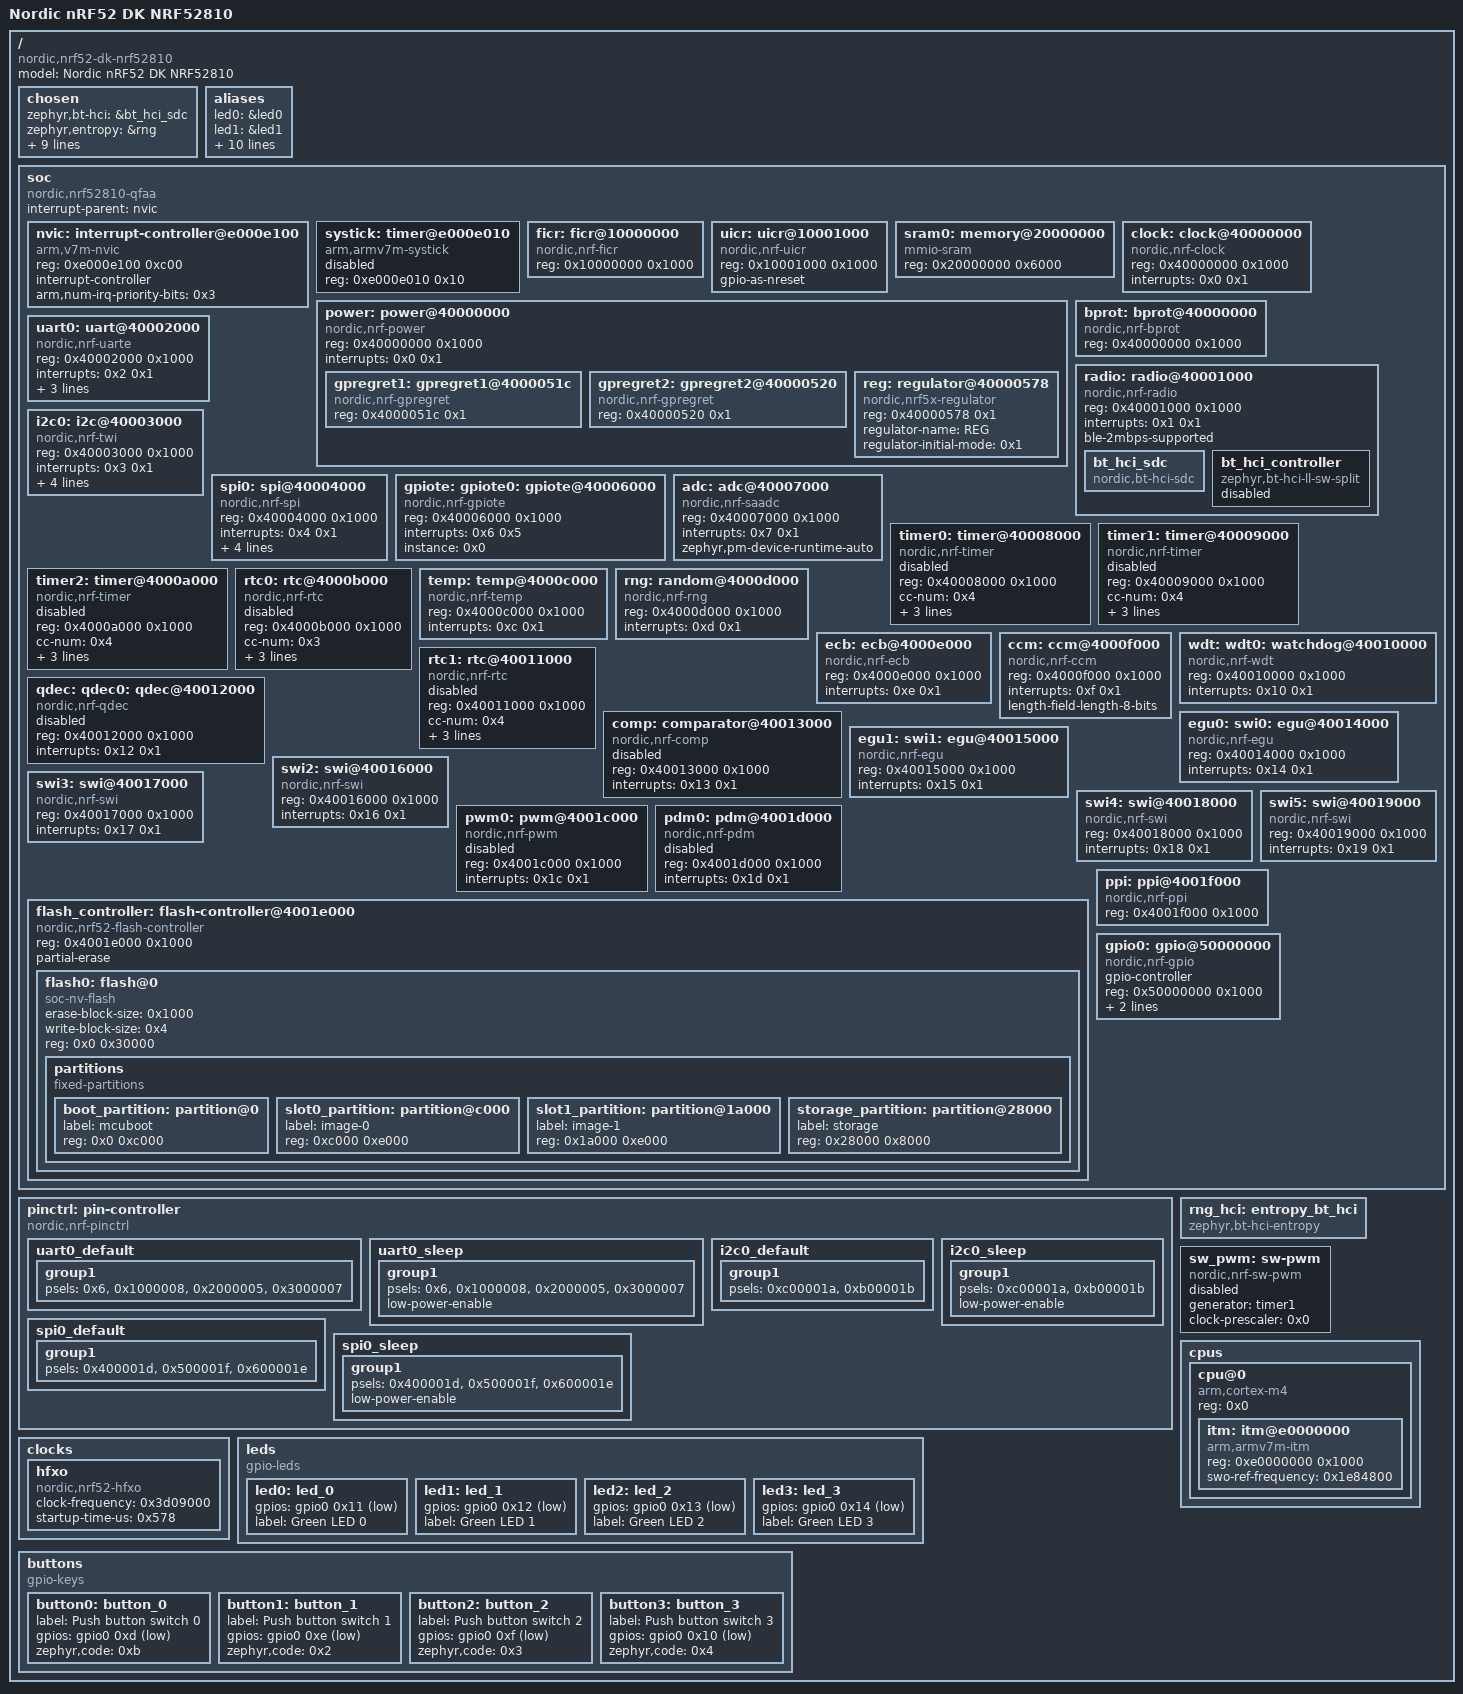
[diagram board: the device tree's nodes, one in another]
/dts-v1/;

/* node '/' defined in zephyr\dts\common\skeleton.dtsi:9 */
/ {
	#address-cells = < 0x1 >;                /* in zephyr\dts\common\skeleton.dtsi:10 */
	#size-cells = < 0x1 >;                   /* in zephyr\dts\common\skeleton.dtsi:11 */
	model = "Nordic nRF52 DK NRF52810";      /* in zephyr\boards\nordic\nrf52dk\nrf52dk_nrf52810.dts:15 */
	compatible = "nordic,nrf52-dk-nrf52810"; /* in zephyr\boards\nordic\nrf52dk\nrf52dk_nrf52810.dts:16 */

	/* node '/chosen' defined in zephyr\dts\common\skeleton.dtsi:12 */
	chosen {
		zephyr,bt-hci = &bt_hci_sdc;                 /* in zephyr\dts\arm\nordic\nrf52810.dtsi:10 */
		zephyr,entropy = &rng;                       /* in zephyr\dts\arm\nordic\nrf52810.dtsi:11 */
		zephyr,flash-controller = &flash_controller; /* in zephyr\dts\arm\nordic\nrf52810.dtsi:12 */
		zephyr,console = &uart0;                     /* in zephyr\boards\nordic\nrf52dk\nrf52dk_nrf52810.dts:19 */
		zephyr,shell-uart = &uart0;                  /* in zephyr\boards\nordic\nrf52dk\nrf52dk_nrf52810.dts:20 */
		zephyr,uart-mcumgr = &uart0;                 /* in zephyr\boards\nordic\nrf52dk\nrf52dk_nrf52810.dts:21 */
		zephyr,bt-mon-uart = &uart0;                 /* in zephyr\boards\nordic\nrf52dk\nrf52dk_nrf52810.dts:22 */
		zephyr,bt-c2h-uart = &uart0;                 /* in zephyr\boards\nordic\nrf52dk\nrf52dk_nrf52810.dts:23 */
		zephyr,sram = &sram0;                        /* in zephyr\boards\nordic\nrf52dk\nrf52dk_nrf52810.dts:24 */
		zephyr,flash = &flash0;                      /* in zephyr\boards\nordic\nrf52dk\nrf52dk_nrf52810.dts:25 */
		zephyr,code-partition = &slot0_partition;    /* in zephyr\boards\nordic\nrf52dk\nrf52dk_nrf52810.dts:26 */
	};

	/* node '/aliases' defined in zephyr\dts\common\skeleton.dtsi:13 */
	aliases {
		led0 = &led0;               /* in zephyr\boards\nordic\nrf52dk\nrf52dk_nrf52810.dts:83 */
		led1 = &led1;               /* in zephyr\boards\nordic\nrf52dk\nrf52dk_nrf52810.dts:84 */
		led2 = &led2;               /* in zephyr\boards\nordic\nrf52dk\nrf52dk_nrf52810.dts:85 */
		led3 = &led3;               /* in zephyr\boards\nordic\nrf52dk\nrf52dk_nrf52810.dts:86 */
		sw0 = &button0;             /* in zephyr\boards\nordic\nrf52dk\nrf52dk_nrf52810.dts:87 */
		sw1 = &button1;             /* in zephyr\boards\nordic\nrf52dk\nrf52dk_nrf52810.dts:88 */
		sw2 = &button2;             /* in zephyr\boards\nordic\nrf52dk\nrf52dk_nrf52810.dts:89 */
		sw3 = &button3;             /* in zephyr\boards\nordic\nrf52dk\nrf52dk_nrf52810.dts:90 */
		bootloader-led0 = &led0;    /* in zephyr\boards\nordic\nrf52dk\nrf52dk_nrf52810.dts:91 */
		mcuboot-button0 = &button0; /* in zephyr\boards\nordic\nrf52dk\nrf52dk_nrf52810.dts:92 */
		mcuboot-led0 = &led0;       /* in zephyr\boards\nordic\nrf52dk\nrf52dk_nrf52810.dts:93 */
		watchdog0 = &wdt0;          /* in zephyr\boards\nordic\nrf52dk\nrf52dk_nrf52810.dts:94 */
	};

	/* node '/soc' defined in zephyr\dts\arm\armv7-m.dtsi:6 */
	soc {
		#address-cells = < 0x1 >;            /* in zephyr\dts\arm\armv7-m.dtsi:7 */
		#size-cells = < 0x1 >;               /* in zephyr\dts\arm\armv7-m.dtsi:8 */
		compatible = "nordic,nrf52810-qfaa",
		             "nordic,nrf52810",
		             "nordic,nrf52",
		             "simple-bus";           /* in zephyr\dts\arm\nordic\nrf52810_qfaa.dtsi:20 */
		interrupt-parent = < &nvic >;        /* in zephyr\dts\arm\armv7-m.dtsi:10 */
		ranges;                              /* in zephyr\dts\arm\armv7-m.dtsi:11 */

		/* node '/soc/interrupt-controller@e000e100' defined in zephyr\dts\arm\armv7-m.dtsi:13 */
		nvic: interrupt-controller@e000e100 {
			#address-cells = < 0x1 >;            /* in zephyr\dts\arm\armv7-m.dtsi:14 */
			compatible = "arm,v7m-nvic";         /* in zephyr\dts\arm\armv7-m.dtsi:15 */
			reg = < 0xe000e100 0xc00 >;          /* in zephyr\dts\arm\armv7-m.dtsi:16 */
			interrupt-controller;                /* in zephyr\dts\arm\armv7-m.dtsi:17 */
			#interrupt-cells = < 0x2 >;          /* in zephyr\dts\arm\armv7-m.dtsi:18 */
			arm,num-irq-priority-bits = < 0x3 >; /* in zephyr\dts\arm\nordic\nrf52810.dtsi:376 */
			phandle = < 0x1 >;                   /* in zephyr\dts\arm\armv7-m.dtsi:10 */
		};

		/* node '/soc/timer@e000e010' defined in zephyr\dts\arm\armv7-m.dtsi:21 */
		systick: timer@e000e010 {
			compatible = "arm,armv7m-systick"; /* in zephyr\dts\arm\armv7-m.dtsi:22 */
			reg = < 0xe000e010 0x10 >;         /* in zephyr\dts\arm\armv7-m.dtsi:23 */
			status = "disabled";               /* in zephyr\dts\arm\nordic\nrf52810.dtsi:381 */
		};

		/* node '/soc/ficr@10000000' defined in zephyr\dts\arm\nordic\nrf52810.dtsi:44 */
		ficr: ficr@10000000 {
			compatible = "nordic,nrf-ficr"; /* in zephyr\dts\arm\nordic\nrf52810.dtsi:45 */
			reg = < 0x10000000 0x1000 >;    /* in zephyr\dts\arm\nordic\nrf52810.dtsi:46 */
			#nordic,ficr-cells = < 0x1 >;   /* in zephyr\dts\arm\nordic\nrf52810.dtsi:47 */
			status = "okay";                /* in zephyr\dts\arm\nordic\nrf52810.dtsi:48 */
		};

		/* node '/soc/uicr@10001000' defined in zephyr\dts\arm\nordic\nrf52810.dtsi:51 */
		uicr: uicr@10001000 {
			compatible = "nordic,nrf-uicr"; /* in zephyr\dts\arm\nordic\nrf52810.dtsi:52 */
			reg = < 0x10001000 0x1000 >;    /* in zephyr\dts\arm\nordic\nrf52810.dtsi:53 */
			status = "okay";                /* in zephyr\dts\arm\nordic\nrf52810.dtsi:54 */
			gpio-as-nreset;                 /* in zephyr\boards\nordic\nrf52dk\nrf52dk_nrf52810.dts:107 */
		};

		/* node '/soc/memory@20000000' defined in zephyr\dts\arm\nordic\nrf52810.dtsi:57 */
		sram0: memory@20000000 {
			compatible = "mmio-sram";    /* in zephyr\dts\arm\nordic\nrf52810.dtsi:58 */
			reg = < 0x20000000 0x6000 >; /* in zephyr\dts\arm\nordic\nrf52810_qfaa.dtsi:15 */
		};

		/* node '/soc/clock@40000000' defined in zephyr\dts\arm\nordic\nrf52810.dtsi:61 */
		clock: clock@40000000 {
			compatible = "nordic,nrf-clock"; /* in zephyr\dts\arm\nordic\nrf52810.dtsi:62 */
			reg = < 0x40000000 0x1000 >;     /* in zephyr\dts\arm\nordic\nrf52810.dtsi:63 */
			interrupts = < 0x0 0x1 >;        /* in zephyr\dts\arm\nordic\nrf52810.dtsi:64 */
			status = "okay";                 /* in zephyr\dts\arm\nordic\nrf52810.dtsi:65 */
		};

		/* node '/soc/power@40000000' defined in zephyr\dts\arm\nordic\nrf52810.dtsi:68 */
		power: power@40000000 {
			compatible = "nordic,nrf-power"; /* in zephyr\dts\arm\nordic\nrf52810.dtsi:69 */
			reg = < 0x40000000 0x1000 >;     /* in zephyr\dts\arm\nordic\nrf52810.dtsi:70 */
			interrupts = < 0x0 0x1 >;        /* in zephyr\dts\arm\nordic\nrf52810.dtsi:71 */
			status = "okay";                 /* in zephyr\dts\arm\nordic\nrf52810.dtsi:72 */
			#address-cells = < 0x1 >;        /* in zephyr\dts\arm\nordic\nrf52810.dtsi:73 */
			#size-cells = < 0x1 >;           /* in zephyr\dts\arm\nordic\nrf52810.dtsi:74 */

			/* node '/soc/power@40000000/gpregret1@4000051c' defined in zephyr\dts\arm\nordic\nrf52810.dtsi:76 */
			gpregret1: gpregret1@4000051c {
				#address-cells = < 0x1 >;           /* in zephyr\dts\arm\nordic\nrf52810.dtsi:77 */
				#size-cells = < 0x1 >;              /* in zephyr\dts\arm\nordic\nrf52810.dtsi:78 */
				compatible = "nordic,nrf-gpregret"; /* in zephyr\dts\arm\nordic\nrf52810.dtsi:79 */
				reg = < 0x4000051c 0x1 >;           /* in zephyr\dts\arm\nordic\nrf52810.dtsi:80 */
				status = "okay";                    /* in zephyr\dts\arm\nordic\nrf52810.dtsi:81 */
			};

			/* node '/soc/power@40000000/gpregret2@40000520' defined in zephyr\dts\arm\nordic\nrf52810.dtsi:84 */
			gpregret2: gpregret2@40000520 {
				#address-cells = < 0x1 >;           /* in zephyr\dts\arm\nordic\nrf52810.dtsi:85 */
				#size-cells = < 0x1 >;              /* in zephyr\dts\arm\nordic\nrf52810.dtsi:86 */
				compatible = "nordic,nrf-gpregret"; /* in zephyr\dts\arm\nordic\nrf52810.dtsi:87 */
				reg = < 0x40000520 0x1 >;           /* in zephyr\dts\arm\nordic\nrf52810.dtsi:88 */
				status = "okay";                    /* in zephyr\dts\arm\nordic\nrf52810.dtsi:89 */
			};

			/* node '/soc/power@40000000/regulator@40000578' defined in zephyr\dts\arm\nordic\nrf52810.dtsi:92 */
			reg: regulator@40000578 {
				compatible = "nordic,nrf5x-regulator"; /* in zephyr\dts\arm\nordic\nrf52810.dtsi:93 */
				reg = < 0x40000578 0x1 >;              /* in zephyr\dts\arm\nordic\nrf52810.dtsi:94 */
				regulator-name = "REG";                /* in zephyr\dts\arm\nordic\nrf52810.dtsi:95 */
				regulator-initial-mode = < 0x1 >;      /* in zephyr\boards\nordic\nrf52dk\nrf52dk_nrf52810.dts:99 */
			};
		};

		/* node '/soc/bprot@40000000' defined in zephyr\dts\arm\nordic\nrf52810.dtsi:100 */
		bprot: bprot@40000000 {
			compatible = "nordic,nrf-bprot"; /* in zephyr\dts\arm\nordic\nrf52810.dtsi:101 */
			reg = < 0x40000000 0x1000 >;     /* in zephyr\dts\arm\nordic\nrf52810.dtsi:102 */
			status = "okay";                 /* in zephyr\dts\arm\nordic\nrf52810.dtsi:103 */
		};

		/* node '/soc/radio@40001000' defined in zephyr\dts\arm\nordic\nrf52810.dtsi:106 */
		radio: radio@40001000 {
			compatible = "nordic,nrf-radio"; /* in zephyr\dts\arm\nordic\nrf52810.dtsi:107 */
			reg = < 0x40001000 0x1000 >;     /* in zephyr\dts\arm\nordic\nrf52810.dtsi:108 */
			interrupts = < 0x1 0x1 >;        /* in zephyr\dts\arm\nordic\nrf52810.dtsi:109 */
			status = "okay";                 /* in zephyr\dts\arm\nordic\nrf52810.dtsi:110 */
			ble-2mbps-supported;             /* in zephyr\dts\arm\nordic\nrf52810.dtsi:111 */

			/* node '/soc/radio@40001000/bt_hci_sdc' defined in zephyr\dts\arm\nordic\nrf52810.dtsi:113 */
			bt_hci_sdc: bt_hci_sdc {
				compatible = "nordic,bt-hci-sdc"; /* in zephyr\dts\arm\nordic\nrf52810.dtsi:114 */
				status = "okay";                  /* in zephyr\dts\arm\nordic\nrf52810.dtsi:115 */
			};

			/* node '/soc/radio@40001000/bt_hci_controller' defined in zephyr\dts\arm\nordic\nrf52810.dtsi:117 */
			bt_hci_controller: bt_hci_controller {
				compatible = "zephyr,bt-hci-ll-sw-split"; /* in zephyr\dts\arm\nordic\nrf52810.dtsi:118 */
				status = "disabled";                      /* in zephyr\dts\arm\nordic\nrf52810.dtsi:119 */
			};
		};

		/* node '/soc/uart@40002000' defined in zephyr\dts\arm\nordic\nrf52810.dtsi:123 */
		uart0: uart@40002000 {
			compatible = "nordic,nrf-uarte"; /* in zephyr\boards\nordic\nrf52dk\nrf52dk_nrf52810.dts:119 */
			reg = < 0x40002000 0x1000 >;     /* in zephyr\dts\arm\nordic\nrf52810.dtsi:127 */
			interrupts = < 0x2 0x1 >;        /* in zephyr\dts\arm\nordic\nrf52810.dtsi:128 */
			status = "okay";                 /* in zephyr\boards\nordic\nrf52dk\nrf52dk_nrf52810.dts:120 */
			current-speed = < 0x1c200 >;     /* in zephyr\boards\nordic\nrf52dk\nrf52dk_nrf52810.dts:121 */
			pinctrl-0 = < &uart0_default >;  /* in zephyr\boards\nordic\nrf52dk\nrf52dk_nrf52810.dts:122 */
			pinctrl-1 = < &uart0_sleep >;    /* in zephyr\boards\nordic\nrf52dk\nrf52dk_nrf52810.dts:123 */
			pinctrl-names = "default",
			                "sleep";         /* in zephyr\boards\nordic\nrf52dk\nrf52dk_nrf52810.dts:124 */
		};

		/* node '/soc/i2c@40003000' defined in zephyr\dts\arm\nordic\nrf52810.dtsi:132 */
		i2c0: i2c@40003000 {
			compatible = "nordic,nrf-twi"; /* in zephyr\boards\nordic\nrf52dk\nrf52dk_nrf52810.dts:128 */
			#address-cells = < 0x1 >;      /* in zephyr\dts\arm\nordic\nrf52810.dtsi:141 */
			#size-cells = < 0x0 >;         /* in zephyr\dts\arm\nordic\nrf52810.dtsi:142 */
			reg = < 0x40003000 0x1000 >;   /* in zephyr\dts\arm\nordic\nrf52810.dtsi:143 */
			interrupts = < 0x3 0x1 >;      /* in zephyr\dts\arm\nordic\nrf52810.dtsi:144 */
			easydma-maxcnt-bits = < 0xa >; /* in zephyr\dts\arm\nordic\nrf52810.dtsi:145 */
			status = "okay";               /* in zephyr\boards\nordic\nrf52dk\nrf52dk_nrf52810.dts:129 */
			zephyr,pm-device-runtime-auto; /* in zephyr\dts\arm\nordic\nrf52810.dtsi:147 */
			pinctrl-0 = < &i2c0_default >; /* in zephyr\boards\nordic\nrf52dk\nrf52dk_nrf52810.dts:130 */
			pinctrl-1 = < &i2c0_sleep >;   /* in zephyr\boards\nordic\nrf52dk\nrf52dk_nrf52810.dts:131 */
			pinctrl-names = "default",
			                "sleep";       /* in zephyr\boards\nordic\nrf52dk\nrf52dk_nrf52810.dts:132 */
		};

		/* node '/soc/spi@40004000' defined in zephyr\dts\arm\nordic\nrf52810.dtsi:150 */
		spi0: spi@40004000 {
			compatible = "nordic,nrf-spi"; /* in zephyr\boards\nordic\nrf52dk\nrf52dk_nrf52810.dts:136 */
			#address-cells = < 0x1 >;      /* in zephyr\dts\arm\nordic\nrf52810.dtsi:159 */
			#size-cells = < 0x0 >;         /* in zephyr\dts\arm\nordic\nrf52810.dtsi:160 */
			reg = < 0x40004000 0x1000 >;   /* in zephyr\dts\arm\nordic\nrf52810.dtsi:161 */
			interrupts = < 0x4 0x1 >;      /* in zephyr\dts\arm\nordic\nrf52810.dtsi:162 */
			max-frequency = < 0x7a1200 >;  /* in zephyr\dts\arm\nordic\nrf52810.dtsi:163 */
			easydma-maxcnt-bits = < 0xa >; /* in zephyr\dts\arm\nordic\nrf52810.dtsi:164 */
			status = "okay";               /* in zephyr\boards\nordic\nrf52dk\nrf52dk_nrf52810.dts:137 */
			pinctrl-0 = < &spi0_default >; /* in zephyr\boards\nordic\nrf52dk\nrf52dk_nrf52810.dts:138 */
			pinctrl-1 = < &spi0_sleep >;   /* in zephyr\boards\nordic\nrf52dk\nrf52dk_nrf52810.dts:139 */
			pinctrl-names = "default",
			                "sleep";       /* in zephyr\boards\nordic\nrf52dk\nrf52dk_nrf52810.dts:140 */
		};

		/* node '/soc/gpiote@40006000' defined in zephyr\dts\arm\nordic\nrf52810.dtsi:168 */
		gpiote: gpiote0: gpiote@40006000 {
			compatible = "nordic,nrf-gpiote"; /* in zephyr\dts\arm\nordic\nrf52810.dtsi:169 */
			reg = < 0x40006000 0x1000 >;      /* in zephyr\dts\arm\nordic\nrf52810.dtsi:170 */
			interrupts = < 0x6 0x5 >;         /* in zephyr\dts\arm\nordic\nrf52810.dtsi:171 */
			status = "okay";                  /* in zephyr\boards\nordic\nrf52dk\nrf52dk_nrf52810.dts:111 */
			instance = < 0x0 >;               /* in zephyr\dts\arm\nordic\nrf52810.dtsi:173 */
			phandle = < 0x8 >;                /* in zephyr\dts\arm\nordic\nrf52810.dtsi:370 */
		};

		/* node '/soc/adc@40007000' defined in zephyr\dts\arm\nordic\nrf52810.dtsi:176 */
		adc: adc@40007000 {
			compatible = "nordic,nrf-saadc"; /* in zephyr\dts\arm\nordic\nrf52810.dtsi:177 */
			reg = < 0x40007000 0x1000 >;     /* in zephyr\dts\arm\nordic\nrf52810.dtsi:178 */
			interrupts = < 0x7 0x1 >;        /* in zephyr\dts\arm\nordic\nrf52810.dtsi:179 */
			status = "okay";                 /* in zephyr\boards\nordic\nrf52dk\nrf52dk_nrf52810.dts:103 */
			#io-channel-cells = < 0x1 >;     /* in zephyr\dts\arm\nordic\nrf52810.dtsi:181 */
			zephyr,pm-device-runtime-auto;   /* in zephyr\dts\arm\nordic\nrf52810.dtsi:182 */
		};

		/* node '/soc/timer@40008000' defined in zephyr\dts\arm\nordic\nrf52810.dtsi:184 */
		timer0: timer@40008000 {
			compatible = "nordic,nrf-timer"; /* in zephyr\dts\arm\nordic\nrf52810.dtsi:185 */
			status = "disabled";             /* in zephyr\dts\arm\nordic\nrf52810.dtsi:186 */
			reg = < 0x40008000 0x1000 >;     /* in zephyr\dts\arm\nordic\nrf52810.dtsi:187 */
			cc-num = < 0x4 >;                /* in zephyr\dts\arm\nordic\nrf52810.dtsi:188 */
			max-bit-width = < 0x20 >;        /* in zephyr\dts\arm\nordic\nrf52810.dtsi:189 */
			interrupts = < 0x8 0x1 >;        /* in zephyr\dts\arm\nordic\nrf52810.dtsi:190 */
			prescaler = < 0x0 >;             /* in zephyr\dts\arm\nordic\nrf52810.dtsi:191 */
		};

		/* node '/soc/timer@40009000' defined in zephyr\dts\arm\nordic\nrf52810.dtsi:194 */
		timer1: timer@40009000 {
			compatible = "nordic,nrf-timer"; /* in zephyr\dts\arm\nordic\nrf52810.dtsi:195 */
			status = "disabled";             /* in zephyr\dts\arm\nordic\nrf52810.dtsi:196 */
			reg = < 0x40009000 0x1000 >;     /* in zephyr\dts\arm\nordic\nrf52810.dtsi:197 */
			cc-num = < 0x4 >;                /* in zephyr\dts\arm\nordic\nrf52810.dtsi:198 */
			max-bit-width = < 0x20 >;        /* in zephyr\dts\arm\nordic\nrf52810.dtsi:199 */
			interrupts = < 0x9 0x1 >;        /* in zephyr\dts\arm\nordic\nrf52810.dtsi:200 */
			prescaler = < 0x0 >;             /* in zephyr\dts\arm\nordic\nrf52810.dtsi:201 */
			phandle = < 0x9 >;               /* in zephyr\dts\vendor\nordic\nrf_common.dtsi:41 */
		};

		/* node '/soc/timer@4000a000' defined in zephyr\dts\arm\nordic\nrf52810.dtsi:204 */
		timer2: timer@4000a000 {
			compatible = "nordic,nrf-timer"; /* in zephyr\dts\arm\nordic\nrf52810.dtsi:205 */
			status = "disabled";             /* in zephyr\dts\arm\nordic\nrf52810.dtsi:206 */
			reg = < 0x4000a000 0x1000 >;     /* in zephyr\dts\arm\nordic\nrf52810.dtsi:207 */
			cc-num = < 0x4 >;                /* in zephyr\dts\arm\nordic\nrf52810.dtsi:208 */
			max-bit-width = < 0x20 >;        /* in zephyr\dts\arm\nordic\nrf52810.dtsi:209 */
			interrupts = < 0xa 0x1 >;        /* in zephyr\dts\arm\nordic\nrf52810.dtsi:210 */
			prescaler = < 0x0 >;             /* in zephyr\dts\arm\nordic\nrf52810.dtsi:211 */
		};

		/* node '/soc/rtc@4000b000' defined in zephyr\dts\arm\nordic\nrf52810.dtsi:214 */
		rtc0: rtc@4000b000 {
			compatible = "nordic,nrf-rtc"; /* in zephyr\dts\arm\nordic\nrf52810.dtsi:215 */
			reg = < 0x4000b000 0x1000 >;   /* in zephyr\dts\arm\nordic\nrf52810.dtsi:216 */
			cc-num = < 0x3 >;              /* in zephyr\dts\arm\nordic\nrf52810.dtsi:217 */
			interrupts = < 0xb 0x1 >;      /* in zephyr\dts\arm\nordic\nrf52810.dtsi:218 */
			status = "disabled";           /* in zephyr\dts\arm\nordic\nrf52810.dtsi:219 */
			clock-frequency = < 0x8000 >;  /* in zephyr\dts\arm\nordic\nrf52810.dtsi:220 */
			prescaler = < 0x1 >;           /* in zephyr\dts\arm\nordic\nrf52810.dtsi:221 */
		};

		/* node '/soc/temp@4000c000' defined in zephyr\dts\arm\nordic\nrf52810.dtsi:224 */
		temp: temp@4000c000 {
			compatible = "nordic,nrf-temp"; /* in zephyr\dts\arm\nordic\nrf52810.dtsi:225 */
			reg = < 0x4000c000 0x1000 >;    /* in zephyr\dts\arm\nordic\nrf52810.dtsi:226 */
			interrupts = < 0xc 0x1 >;       /* in zephyr\dts\arm\nordic\nrf52810.dtsi:227 */
			status = "okay";                /* in zephyr\dts\arm\nordic\nrf52810.dtsi:228 */
		};

		/* node '/soc/random@4000d000' defined in zephyr\dts\arm\nordic\nrf52810.dtsi:231 */
		rng: random@4000d000 {
			compatible = "nordic,nrf-rng"; /* in zephyr\dts\arm\nordic\nrf52810.dtsi:232 */
			reg = < 0x4000d000 0x1000 >;   /* in zephyr\dts\arm\nordic\nrf52810.dtsi:233 */
			interrupts = < 0xd 0x1 >;      /* in zephyr\dts\arm\nordic\nrf52810.dtsi:234 */
			status = "okay";               /* in zephyr\dts\arm\nordic\nrf52810.dtsi:235 */
		};

		/* node '/soc/ecb@4000e000' defined in zephyr\dts\arm\nordic\nrf52810.dtsi:238 */
		ecb: ecb@4000e000 {
			compatible = "nordic,nrf-ecb"; /* in zephyr\dts\arm\nordic\nrf52810.dtsi:239 */
			reg = < 0x4000e000 0x1000 >;   /* in zephyr\dts\arm\nordic\nrf52810.dtsi:240 */
			interrupts = < 0xe 0x1 >;      /* in zephyr\dts\arm\nordic\nrf52810.dtsi:241 */
			status = "okay";               /* in zephyr\dts\arm\nordic\nrf52810.dtsi:242 */
		};

		/* node '/soc/ccm@4000f000' defined in zephyr\dts\arm\nordic\nrf52810.dtsi:245 */
		ccm: ccm@4000f000 {
			compatible = "nordic,nrf-ccm"; /* in zephyr\dts\arm\nordic\nrf52810.dtsi:246 */
			reg = < 0x4000f000 0x1000 >;   /* in zephyr\dts\arm\nordic\nrf52810.dtsi:247 */
			interrupts = < 0xf 0x1 >;      /* in zephyr\dts\arm\nordic\nrf52810.dtsi:248 */
			length-field-length-8-bits;    /* in zephyr\dts\arm\nordic\nrf52810.dtsi:249 */
			status = "okay";               /* in zephyr\dts\arm\nordic\nrf52810.dtsi:250 */
		};

		/* node '/soc/watchdog@40010000' defined in zephyr\dts\arm\nordic\nrf52810.dtsi:253 */
		wdt: wdt0: watchdog@40010000 {
			compatible = "nordic,nrf-wdt"; /* in zephyr\dts\arm\nordic\nrf52810.dtsi:254 */
			reg = < 0x40010000 0x1000 >;   /* in zephyr\dts\arm\nordic\nrf52810.dtsi:255 */
			interrupts = < 0x10 0x1 >;     /* in zephyr\dts\arm\nordic\nrf52810.dtsi:256 */
			status = "okay";               /* in zephyr\dts\arm\nordic\nrf52810.dtsi:257 */
		};

		/* node '/soc/rtc@40011000' defined in zephyr\dts\arm\nordic\nrf52810.dtsi:260 */
		rtc1: rtc@40011000 {
			compatible = "nordic,nrf-rtc"; /* in zephyr\dts\arm\nordic\nrf52810.dtsi:261 */
			reg = < 0x40011000 0x1000 >;   /* in zephyr\dts\arm\nordic\nrf52810.dtsi:262 */
			cc-num = < 0x4 >;              /* in zephyr\dts\arm\nordic\nrf52810.dtsi:263 */
			interrupts = < 0x11 0x1 >;     /* in zephyr\dts\arm\nordic\nrf52810.dtsi:264 */
			status = "disabled";           /* in zephyr\dts\arm\nordic\nrf52810.dtsi:265 */
			clock-frequency = < 0x8000 >;  /* in zephyr\dts\arm\nordic\nrf52810.dtsi:266 */
			prescaler = < 0x1 >;           /* in zephyr\dts\arm\nordic\nrf52810.dtsi:267 */
		};

		/* node '/soc/qdec@40012000' defined in zephyr\dts\arm\nordic\nrf52810.dtsi:270 */
		qdec: qdec0: qdec@40012000 {
			compatible = "nordic,nrf-qdec"; /* in zephyr\dts\arm\nordic\nrf52810.dtsi:271 */
			reg = < 0x40012000 0x1000 >;    /* in zephyr\dts\arm\nordic\nrf52810.dtsi:272 */
			interrupts = < 0x12 0x1 >;      /* in zephyr\dts\arm\nordic\nrf52810.dtsi:273 */
			status = "disabled";            /* in zephyr\dts\arm\nordic\nrf52810.dtsi:274 */
		};

		/* node '/soc/comparator@40013000' defined in zephyr\dts\arm\nordic\nrf52810.dtsi:277 */
		comp: comparator@40013000 {
			compatible = "nordic,nrf-comp"; /* in zephyr\dts\arm\nordic\nrf52810.dtsi:278 */
			reg = < 0x40013000 0x1000 >;    /* in zephyr\dts\arm\nordic\nrf52810.dtsi:279 */
			interrupts = < 0x13 0x1 >;      /* in zephyr\dts\arm\nordic\nrf52810.dtsi:280 */
			status = "disabled";            /* in zephyr\dts\arm\nordic\nrf52810.dtsi:281 */
		};

		/* node '/soc/egu@40014000' defined in zephyr\dts\arm\nordic\nrf52810.dtsi:284 */
		egu0: swi0: egu@40014000 {
			compatible = "nordic,nrf-egu",
			             "nordic,nrf-swi"; /* in zephyr\dts\arm\nordic\nrf52810.dtsi:285 */
			reg = < 0x40014000 0x1000 >;   /* in zephyr\dts\arm\nordic\nrf52810.dtsi:286 */
			interrupts = < 0x14 0x1 >;     /* in zephyr\dts\arm\nordic\nrf52810.dtsi:287 */
			status = "okay";               /* in zephyr\dts\arm\nordic\nrf52810.dtsi:288 */
		};

		/* node '/soc/egu@40015000' defined in zephyr\dts\arm\nordic\nrf52810.dtsi:291 */
		egu1: swi1: egu@40015000 {
			compatible = "nordic,nrf-egu",
			             "nordic,nrf-swi"; /* in zephyr\dts\arm\nordic\nrf52810.dtsi:292 */
			reg = < 0x40015000 0x1000 >;   /* in zephyr\dts\arm\nordic\nrf52810.dtsi:293 */
			interrupts = < 0x15 0x1 >;     /* in zephyr\dts\arm\nordic\nrf52810.dtsi:294 */
			status = "okay";               /* in zephyr\dts\arm\nordic\nrf52810.dtsi:295 */
		};

		/* node '/soc/swi@40016000' defined in zephyr\dts\arm\nordic\nrf52810.dtsi:298 */
		swi2: swi@40016000 {
			compatible = "nordic,nrf-swi"; /* in zephyr\dts\arm\nordic\nrf52810.dtsi:299 */
			reg = < 0x40016000 0x1000 >;   /* in zephyr\dts\arm\nordic\nrf52810.dtsi:300 */
			interrupts = < 0x16 0x1 >;     /* in zephyr\dts\arm\nordic\nrf52810.dtsi:301 */
			status = "okay";               /* in zephyr\dts\arm\nordic\nrf52810.dtsi:302 */
		};

		/* node '/soc/swi@40017000' defined in zephyr\dts\arm\nordic\nrf52810.dtsi:305 */
		swi3: swi@40017000 {
			compatible = "nordic,nrf-swi"; /* in zephyr\dts\arm\nordic\nrf52810.dtsi:306 */
			reg = < 0x40017000 0x1000 >;   /* in zephyr\dts\arm\nordic\nrf52810.dtsi:307 */
			interrupts = < 0x17 0x1 >;     /* in zephyr\dts\arm\nordic\nrf52810.dtsi:308 */
			status = "okay";               /* in zephyr\dts\arm\nordic\nrf52810.dtsi:309 */
		};

		/* node '/soc/swi@40018000' defined in zephyr\dts\arm\nordic\nrf52810.dtsi:312 */
		swi4: swi@40018000 {
			compatible = "nordic,nrf-swi"; /* in zephyr\dts\arm\nordic\nrf52810.dtsi:313 */
			reg = < 0x40018000 0x1000 >;   /* in zephyr\dts\arm\nordic\nrf52810.dtsi:314 */
			interrupts = < 0x18 0x1 >;     /* in zephyr\dts\arm\nordic\nrf52810.dtsi:315 */
			status = "okay";               /* in zephyr\dts\arm\nordic\nrf52810.dtsi:316 */
		};

		/* node '/soc/swi@40019000' defined in zephyr\dts\arm\nordic\nrf52810.dtsi:319 */
		swi5: swi@40019000 {
			compatible = "nordic,nrf-swi"; /* in zephyr\dts\arm\nordic\nrf52810.dtsi:320 */
			reg = < 0x40019000 0x1000 >;   /* in zephyr\dts\arm\nordic\nrf52810.dtsi:321 */
			interrupts = < 0x19 0x1 >;     /* in zephyr\dts\arm\nordic\nrf52810.dtsi:322 */
			status = "okay";               /* in zephyr\dts\arm\nordic\nrf52810.dtsi:323 */
		};

		/* node '/soc/pwm@4001c000' defined in zephyr\dts\arm\nordic\nrf52810.dtsi:326 */
		pwm0: pwm@4001c000 {
			compatible = "nordic,nrf-pwm"; /* in zephyr\dts\arm\nordic\nrf52810.dtsi:327 */
			reg = < 0x4001c000 0x1000 >;   /* in zephyr\dts\arm\nordic\nrf52810.dtsi:328 */
			interrupts = < 0x1c 0x1 >;     /* in zephyr\dts\arm\nordic\nrf52810.dtsi:329 */
			status = "disabled";           /* in zephyr\dts\arm\nordic\nrf52810.dtsi:330 */
			#pwm-cells = < 0x3 >;          /* in zephyr\dts\arm\nordic\nrf52810.dtsi:331 */
		};

		/* node '/soc/pdm@4001d000' defined in zephyr\dts\arm\nordic\nrf52810.dtsi:334 */
		pdm0: pdm@4001d000 {
			compatible = "nordic,nrf-pdm"; /* in zephyr\dts\arm\nordic\nrf52810.dtsi:335 */
			reg = < 0x4001d000 0x1000 >;   /* in zephyr\dts\arm\nordic\nrf52810.dtsi:336 */
			interrupts = < 0x1d 0x1 >;     /* in zephyr\dts\arm\nordic\nrf52810.dtsi:337 */
			status = "disabled";           /* in zephyr\dts\arm\nordic\nrf52810.dtsi:338 */
		};

		/* node '/soc/flash-controller@4001e000' defined in zephyr\dts\arm\nordic\nrf52810.dtsi:341 */
		flash_controller: flash-controller@4001e000 {
			compatible = "nordic,nrf52-flash-controller"; /* in zephyr\dts\arm\nordic\nrf52810.dtsi:342 */
			reg = < 0x4001e000 0x1000 >;                  /* in zephyr\dts\arm\nordic\nrf52810.dtsi:343 */
			partial-erase;                                /* in zephyr\dts\arm\nordic\nrf52810.dtsi:344 */
			#address-cells = < 0x1 >;                     /* in zephyr\dts\arm\nordic\nrf52810.dtsi:346 */
			#size-cells = < 0x1 >;                        /* in zephyr\dts\arm\nordic\nrf52810.dtsi:347 */

			/* node '/soc/flash-controller@4001e000/flash@0' defined in zephyr\dts\arm\nordic\nrf52810.dtsi:350 */
			flash0: flash@0 {
				compatible = "soc-nv-flash";   /* in zephyr\dts\arm\nordic\nrf52810.dtsi:351 */
				erase-block-size = < 0x1000 >; /* in zephyr\dts\arm\nordic\nrf52810.dtsi:352 */
				write-block-size = < 0x4 >;    /* in zephyr\dts\arm\nordic\nrf52810.dtsi:353 */
				reg = < 0x0 0x30000 >;         /* in zephyr\dts\arm\nordic\nrf52810_qfaa.dtsi:11 */

				/* node '/soc/flash-controller@4001e000/flash@0/partitions' defined in zephyr\boards\nordic\nrf52dk\nrf52dk_nrf52810.dts:144 */
				partitions {
					compatible = "fixed-partitions"; /* in zephyr\boards\nordic\nrf52dk\nrf52dk_nrf52810.dts:145 */
					#address-cells = < 0x1 >;        /* in zephyr\boards\nordic\nrf52dk\nrf52dk_nrf52810.dts:146 */
					#size-cells = < 0x1 >;           /* in zephyr\boards\nordic\nrf52dk\nrf52dk_nrf52810.dts:147 */

					/* node '/soc/flash-controller@4001e000/flash@0/partitions/partition@0' defined in zephyr\boards\nordic\nrf52dk\nrf52dk_nrf52810.dts:149 */
					boot_partition: partition@0 {
						label = "mcuboot";    /* in zephyr\boards\nordic\nrf52dk\nrf52dk_nrf52810.dts:150 */
						reg = < 0x0 0xc000 >; /* in zephyr\boards\nordic\nrf52dk\nrf52dk_nrf52810.dts:151 */
					};

					/* node '/soc/flash-controller@4001e000/flash@0/partitions/partition@c000' defined in zephyr\boards\nordic\nrf52dk\nrf52dk_nrf52810.dts:154 */
					slot0_partition: partition@c000 {
						label = "image-0";       /* in zephyr\boards\nordic\nrf52dk\nrf52dk_nrf52810.dts:155 */
						reg = < 0xc000 0xe000 >; /* in zephyr\boards\nordic\nrf52dk\nrf52dk_nrf52810.dts:156 */
					};

					/* node '/soc/flash-controller@4001e000/flash@0/partitions/partition@1a000' defined in zephyr\boards\nordic\nrf52dk\nrf52dk_nrf52810.dts:159 */
					slot1_partition: partition@1a000 {
						label = "image-1";        /* in zephyr\boards\nordic\nrf52dk\nrf52dk_nrf52810.dts:160 */
						reg = < 0x1a000 0xe000 >; /* in zephyr\boards\nordic\nrf52dk\nrf52dk_nrf52810.dts:161 */
					};

					/* node '/soc/flash-controller@4001e000/flash@0/partitions/partition@28000' defined in zephyr\boards\nordic\nrf52dk\nrf52dk_nrf52810.dts:164 */
					storage_partition: partition@28000 {
						label = "storage";        /* in zephyr\boards\nordic\nrf52dk\nrf52dk_nrf52810.dts:165 */
						reg = < 0x28000 0x8000 >; /* in zephyr\boards\nordic\nrf52dk\nrf52dk_nrf52810.dts:166 */
					};
				};
			};
		};

		/* node '/soc/ppi@4001f000' defined in zephyr\dts\arm\nordic\nrf52810.dtsi:357 */
		ppi: ppi@4001f000 {
			compatible = "nordic,nrf-ppi"; /* in zephyr\dts\arm\nordic\nrf52810.dtsi:358 */
			reg = < 0x4001f000 0x1000 >;   /* in zephyr\dts\arm\nordic\nrf52810.dtsi:359 */
			status = "okay";               /* in zephyr\dts\arm\nordic\nrf52810.dtsi:360 */
		};

		/* node '/soc/gpio@50000000' defined in zephyr\dts\arm\nordic\nrf52810.dtsi:363 */
		gpio0: gpio@50000000 {
			compatible = "nordic,nrf-gpio"; /* in zephyr\dts\arm\nordic\nrf52810.dtsi:364 */
			gpio-controller;                /* in zephyr\dts\arm\nordic\nrf52810.dtsi:365 */
			reg = < 0x50000000 0x1000 >;    /* in zephyr\dts\arm\nordic\nrf52810.dtsi:366 */
			#gpio-cells = < 0x2 >;          /* in zephyr\dts\arm\nordic\nrf52810.dtsi:367 */
			status = "okay";                /* in zephyr\boards\nordic\nrf52dk\nrf52dk_nrf52810.dts:115 */
			port = < 0x0 >;                 /* in zephyr\dts\arm\nordic\nrf52810.dtsi:369 */
			gpiote-instance = < &gpiote >;  /* in zephyr\dts\arm\nordic\nrf52810.dtsi:370 */
			phandle = < 0xa >;              /* in zephyr\boards\nordic\nrf52dk\nrf52dk_nrf52810.dts:33 */
		};
	};

	/* node '/pin-controller' defined in zephyr\dts\vendor\nordic\nrf_common.dtsi:25 */
	pinctrl: pin-controller {
		compatible = "nordic,nrf-pinctrl"; /* in zephyr\dts\vendor\nordic\nrf_common.dtsi:30 */

		/* node '/pin-controller/uart0_default' defined in zephyr\boards\nordic\nrf52dk\nrf52dk_nrf52810-pinctrl.dtsi:7 */
		uart0_default: uart0_default {
			phandle = < 0x2 >; /* in zephyr\boards\nordic\nrf52dk\nrf52dk_nrf52810.dts:122 */

			/* node '/pin-controller/uart0_default/group1' defined in zephyr\boards\nordic\nrf52dk\nrf52dk_nrf52810-pinctrl.dtsi:8 */
			group1 {
				psels = < 0x6 >,
				        < 0x1000008 >,
				        < 0x2000005 >,
				        < 0x3000007 >; /* in zephyr\boards\nordic\nrf52dk\nrf52dk_nrf52810-pinctrl.dtsi:9 */
			};
		};

		/* node '/pin-controller/uart0_sleep' defined in zephyr\boards\nordic\nrf52dk\nrf52dk_nrf52810-pinctrl.dtsi:16 */
		uart0_sleep: uart0_sleep {
			phandle = < 0x3 >; /* in zephyr\boards\nordic\nrf52dk\nrf52dk_nrf52810.dts:123 */

			/* node '/pin-controller/uart0_sleep/group1' defined in zephyr\boards\nordic\nrf52dk\nrf52dk_nrf52810-pinctrl.dtsi:17 */
			group1 {
				psels = < 0x6 >,
				        < 0x1000008 >,
				        < 0x2000005 >,
				        < 0x3000007 >; /* in zephyr\boards\nordic\nrf52dk\nrf52dk_nrf52810-pinctrl.dtsi:18 */
				low-power-enable;      /* in zephyr\boards\nordic\nrf52dk\nrf52dk_nrf52810-pinctrl.dtsi:22 */
			};
		};

		/* node '/pin-controller/i2c0_default' defined in zephyr\boards\nordic\nrf52dk\nrf52dk_nrf52810-pinctrl.dtsi:26 */
		i2c0_default: i2c0_default {
			phandle = < 0x4 >; /* in zephyr\boards\nordic\nrf52dk\nrf52dk_nrf52810.dts:130 */

			/* node '/pin-controller/i2c0_default/group1' defined in zephyr\boards\nordic\nrf52dk\nrf52dk_nrf52810-pinctrl.dtsi:27 */
			group1 {
				psels = < 0xc00001a >,
				        < 0xb00001b >; /* in zephyr\boards\nordic\nrf52dk\nrf52dk_nrf52810-pinctrl.dtsi:28 */
			};
		};

		/* node '/pin-controller/i2c0_sleep' defined in zephyr\boards\nordic\nrf52dk\nrf52dk_nrf52810-pinctrl.dtsi:33 */
		i2c0_sleep: i2c0_sleep {
			phandle = < 0x5 >; /* in zephyr\boards\nordic\nrf52dk\nrf52dk_nrf52810.dts:131 */

			/* node '/pin-controller/i2c0_sleep/group1' defined in zephyr\boards\nordic\nrf52dk\nrf52dk_nrf52810-pinctrl.dtsi:34 */
			group1 {
				psels = < 0xc00001a >,
				        < 0xb00001b >; /* in zephyr\boards\nordic\nrf52dk\nrf52dk_nrf52810-pinctrl.dtsi:35 */
				low-power-enable;      /* in zephyr\boards\nordic\nrf52dk\nrf52dk_nrf52810-pinctrl.dtsi:37 */
			};
		};

		/* node '/pin-controller/spi0_default' defined in zephyr\boards\nordic\nrf52dk\nrf52dk_nrf52810-pinctrl.dtsi:41 */
		spi0_default: spi0_default {
			phandle = < 0x6 >; /* in zephyr\boards\nordic\nrf52dk\nrf52dk_nrf52810.dts:138 */

			/* node '/pin-controller/spi0_default/group1' defined in zephyr\boards\nordic\nrf52dk\nrf52dk_nrf52810-pinctrl.dtsi:42 */
			group1 {
				psels = < 0x400001d >,
				        < 0x500001f >,
				        < 0x600001e >; /* in zephyr\boards\nordic\nrf52dk\nrf52dk_nrf52810-pinctrl.dtsi:43 */
			};
		};

		/* node '/pin-controller/spi0_sleep' defined in zephyr\boards\nordic\nrf52dk\nrf52dk_nrf52810-pinctrl.dtsi:49 */
		spi0_sleep: spi0_sleep {
			phandle = < 0x7 >; /* in zephyr\boards\nordic\nrf52dk\nrf52dk_nrf52810.dts:139 */

			/* node '/pin-controller/spi0_sleep/group1' defined in zephyr\boards\nordic\nrf52dk\nrf52dk_nrf52810-pinctrl.dtsi:50 */
			group1 {
				psels = < 0x400001d >,
				        < 0x500001f >,
				        < 0x600001e >; /* in zephyr\boards\nordic\nrf52dk\nrf52dk_nrf52810-pinctrl.dtsi:51 */
				low-power-enable;      /* in zephyr\boards\nordic\nrf52dk\nrf52dk_nrf52810-pinctrl.dtsi:54 */
			};
		};
	};

	/* node '/entropy_bt_hci' defined in zephyr\dts\vendor\nordic\nrf_common.dtsi:33 */
	rng_hci: entropy_bt_hci {
		compatible = "zephyr,bt-hci-entropy"; /* in zephyr\dts\vendor\nordic\nrf_common.dtsi:34 */
		status = "okay";                      /* in zephyr\dts\vendor\nordic\nrf_common.dtsi:35 */
	};

	/* node '/sw-pwm' defined in zephyr\dts\vendor\nordic\nrf_common.dtsi:38 */
	sw_pwm: sw-pwm {
		compatible = "nordic,nrf-sw-pwm"; /* in zephyr\dts\vendor\nordic\nrf_common.dtsi:39 */
		status = "disabled";              /* in zephyr\dts\vendor\nordic\nrf_common.dtsi:40 */
		generator = < &timer1 >;          /* in zephyr\dts\vendor\nordic\nrf_common.dtsi:41 */
		clock-prescaler = < 0x0 >;        /* in zephyr\dts\vendor\nordic\nrf_common.dtsi:42 */
		#pwm-cells = < 0x3 >;             /* in zephyr\dts\vendor\nordic\nrf_common.dtsi:43 */
	};

	/* node '/cpus' defined in zephyr\dts\arm\nordic\nrf52810.dtsi:15 */
	cpus {
		#address-cells = < 0x1 >; /* in zephyr\dts\arm\nordic\nrf52810.dtsi:16 */
		#size-cells = < 0x0 >;    /* in zephyr\dts\arm\nordic\nrf52810.dtsi:17 */

		/* node '/cpus/cpu@0' defined in zephyr\dts\arm\nordic\nrf52810.dtsi:19 */
		cpu@0 {
			device_type = "cpu";          /* in zephyr\dts\arm\nordic\nrf52810.dtsi:20 */
			compatible = "arm,cortex-m4"; /* in zephyr\dts\arm\nordic\nrf52810.dtsi:21 */
			reg = < 0x0 >;                /* in zephyr\dts\arm\nordic\nrf52810.dtsi:22 */
			#address-cells = < 0x1 >;     /* in zephyr\dts\arm\nordic\nrf52810.dtsi:23 */
			#size-cells = < 0x1 >;        /* in zephyr\dts\arm\nordic\nrf52810.dtsi:24 */

			/* node '/cpus/cpu@0/itm@e0000000' defined in zephyr\dts\arm\nordic\nrf52810.dtsi:26 */
			itm: itm@e0000000 {
				compatible = "arm,armv7m-itm";     /* in zephyr\dts\arm\nordic\nrf52810.dtsi:27 */
				reg = < 0xe0000000 0x1000 >;       /* in zephyr\dts\arm\nordic\nrf52810.dtsi:28 */
				swo-ref-frequency = < 0x1e84800 >; /* in zephyr\dts\arm\nordic\nrf52810.dtsi:29 */
			};
		};
	};

	/* node '/clocks' defined in zephyr\dts\arm\nordic\nrf52810.dtsi:34 */
	clocks {

		/* node '/clocks/hfxo' defined in zephyr\dts\arm\nordic\nrf52810.dtsi:35 */
		hfxo: hfxo {
			compatible = "nordic,nrf52-hfxo"; /* in zephyr\dts\arm\nordic\nrf52810.dtsi:36 */
			clock-frequency = < 0x3d09000 >;  /* in zephyr\dts\arm\nordic\nrf52810.dtsi:37 */
			startup-time-us = < 0x578 >;      /* in zephyr\dts\arm\nordic\nrf52810.dtsi:38 */
			#clock-cells = < 0x0 >;           /* in zephyr\dts\arm\nordic\nrf52810.dtsi:39 */
		};
	};

	/* node '/leds' defined in zephyr\boards\nordic\nrf52dk\nrf52dk_nrf52810.dts:29 */
	leds {
		compatible = "gpio-leds"; /* in zephyr\boards\nordic\nrf52dk\nrf52dk_nrf52810.dts:30 */

		/* node '/leds/led_0' defined in zephyr\boards\nordic\nrf52dk\nrf52dk_nrf52810.dts:32 */
		led0: led_0 {
			gpios = < &gpio0 0x11 0x1 >; /* in zephyr\boards\nordic\nrf52dk\nrf52dk_nrf52810.dts:33 */
			label = "Green LED 0";       /* in zephyr\boards\nordic\nrf52dk\nrf52dk_nrf52810.dts:34 */
		};

		/* node '/leds/led_1' defined in zephyr\boards\nordic\nrf52dk\nrf52dk_nrf52810.dts:37 */
		led1: led_1 {
			gpios = < &gpio0 0x12 0x1 >; /* in zephyr\boards\nordic\nrf52dk\nrf52dk_nrf52810.dts:38 */
			label = "Green LED 1";       /* in zephyr\boards\nordic\nrf52dk\nrf52dk_nrf52810.dts:39 */
		};

		/* node '/leds/led_2' defined in zephyr\boards\nordic\nrf52dk\nrf52dk_nrf52810.dts:42 */
		led2: led_2 {
			gpios = < &gpio0 0x13 0x1 >; /* in zephyr\boards\nordic\nrf52dk\nrf52dk_nrf52810.dts:43 */
			label = "Green LED 2";       /* in zephyr\boards\nordic\nrf52dk\nrf52dk_nrf52810.dts:44 */
		};

		/* node '/leds/led_3' defined in zephyr\boards\nordic\nrf52dk\nrf52dk_nrf52810.dts:47 */
		led3: led_3 {
			gpios = < &gpio0 0x14 0x1 >; /* in zephyr\boards\nordic\nrf52dk\nrf52dk_nrf52810.dts:48 */
			label = "Green LED 3";       /* in zephyr\boards\nordic\nrf52dk\nrf52dk_nrf52810.dts:49 */
		};
	};

	/* node '/buttons' defined in zephyr\boards\nordic\nrf52dk\nrf52dk_nrf52810.dts:53 */
	buttons {
		compatible = "gpio-keys"; /* in zephyr\boards\nordic\nrf52dk\nrf52dk_nrf52810.dts:54 */

		/* node '/buttons/button_0' defined in zephyr\boards\nordic\nrf52dk\nrf52dk_nrf52810.dts:56 */
		button0: button_0 {
			label = "Push button switch 0"; /* in zephyr\boards\nordic\nrf52dk\nrf52dk_nrf52810.dts:57 */
			gpios = < &gpio0 0xd 0x11 >;    /* in zephyr\boards\nordic\nrf52dk\nrf52dk_nrf52810.dts:58 */
			zephyr,code = < 0xb >;          /* in zephyr\boards\nordic\nrf52dk\nrf52dk_nrf52810.dts:59 */
		};

		/* node '/buttons/button_1' defined in zephyr\boards\nordic\nrf52dk\nrf52dk_nrf52810.dts:62 */
		button1: button_1 {
			label = "Push button switch 1"; /* in zephyr\boards\nordic\nrf52dk\nrf52dk_nrf52810.dts:63 */
			gpios = < &gpio0 0xe 0x11 >;    /* in zephyr\boards\nordic\nrf52dk\nrf52dk_nrf52810.dts:64 */
			zephyr,code = < 0x2 >;          /* in zephyr\boards\nordic\nrf52dk\nrf52dk_nrf52810.dts:65 */
		};

		/* node '/buttons/button_2' defined in zephyr\boards\nordic\nrf52dk\nrf52dk_nrf52810.dts:68 */
		button2: button_2 {
			label = "Push button switch 2"; /* in zephyr\boards\nordic\nrf52dk\nrf52dk_nrf52810.dts:69 */
			gpios = < &gpio0 0xf 0x11 >;    /* in zephyr\boards\nordic\nrf52dk\nrf52dk_nrf52810.dts:70 */
			zephyr,code = < 0x3 >;          /* in zephyr\boards\nordic\nrf52dk\nrf52dk_nrf52810.dts:71 */
		};

		/* node '/buttons/button_3' defined in zephyr\boards\nordic\nrf52dk\nrf52dk_nrf52810.dts:74 */
		button3: button_3 {
			label = "Push button switch 3"; /* in zephyr\boards\nordic\nrf52dk\nrf52dk_nrf52810.dts:75 */
			gpios = < &gpio0 0x10 0x11 >;   /* in zephyr\boards\nordic\nrf52dk\nrf52dk_nrf52810.dts:76 */
			zephyr,code = < 0x4 >;          /* in zephyr\boards\nordic\nrf52dk\nrf52dk_nrf52810.dts:77 */
		};
	};
};
